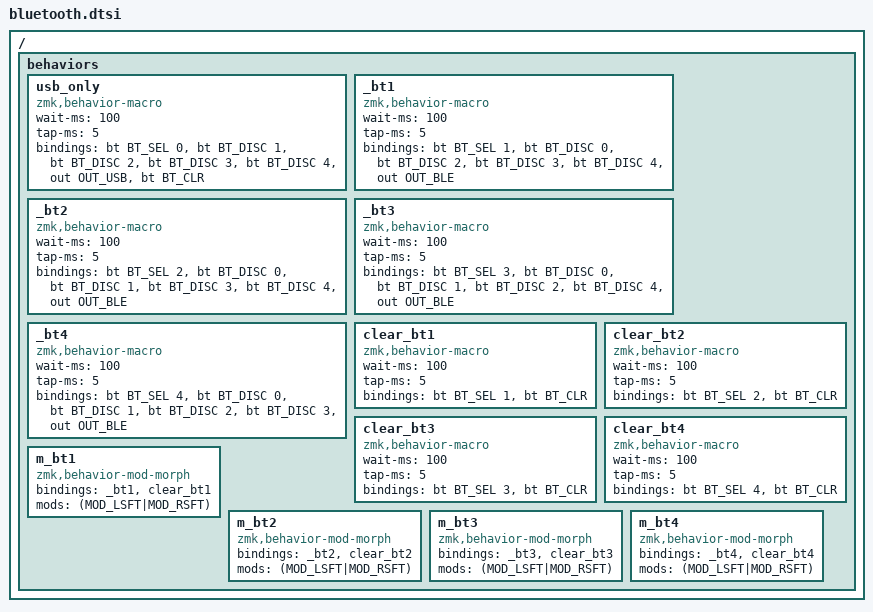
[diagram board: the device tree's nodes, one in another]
#include "include/helper.h"
#include <dt-bindings/zmk/bt.h>

ZMK_MACRO(usb_only,
  wait-ms = <100>;
  tap-ms = <5>;
  bindings = <&bt BT_SEL 0 &bt BT_DISC 1 &bt BT_DISC 2 &bt BT_DISC 3 &bt BT_DISC 4 &out OUT_USB &bt BT_CLR>;
)
ZMK_MACRO(_bt1,
  wait-ms = <100>;
  tap-ms = <5>;
  bindings = <&bt BT_SEL 1 &bt BT_DISC 0 &bt BT_DISC 2 &bt BT_DISC 3 &bt BT_DISC 4 &out OUT_BLE>;
)
ZMK_MACRO(_bt2,
  wait-ms = <100>;
  tap-ms = <5>;
  bindings = <&bt BT_SEL 2 &bt BT_DISC 0 &bt BT_DISC 1 &bt BT_DISC 3 &bt BT_DISC 4 &out OUT_BLE>;
)
ZMK_MACRO(_bt3,
  wait-ms = <100>;
  tap-ms = <5>;
  bindings = <&bt BT_SEL 3 &bt BT_DISC 0 &bt BT_DISC 1 &bt BT_DISC 2 &bt BT_DISC 4 &out OUT_BLE>;
)
ZMK_MACRO(_bt4,
  wait-ms = <100>;
  tap-ms = <5>;
  bindings = <&bt BT_SEL 4 &bt BT_DISC 0 &bt BT_DISC 1 &bt BT_DISC 2 &bt BT_DISC 3 &out OUT_BLE>;
)
ZMK_MACRO(clear_bt1,
  wait-ms = <100>;
  tap-ms = <5>;
  bindings = <&bt BT_SEL 1 &bt BT_CLR>;
)
ZMK_MACRO(clear_bt2,
  wait-ms = <100>;
  tap-ms = <5>;
  bindings = <&bt BT_SEL 2 &bt BT_CLR>;
)
ZMK_MACRO(clear_bt3,
  wait-ms = <100>;
  tap-ms = <5>;
  bindings = <&bt BT_SEL 3 &bt BT_CLR>;
)
ZMK_MACRO(clear_bt4,
  wait-ms = <100>;
  tap-ms = <5>;
  bindings = <&bt BT_SEL 4 &bt BT_CLR>;
)

ZMK_MOD_MORPH(m_bt1,
  bindings = <&_bt1>, <&clear_bt1>;
  mods = <(MOD_LSFT|MOD_RSFT)>;
  )

ZMK_MOD_MORPH(m_bt2,
  bindings = <&_bt2>, <&clear_bt2>;
  mods = <(MOD_LSFT|MOD_RSFT)>;
)

ZMK_MOD_MORPH(m_bt3,
  bindings = <&_bt3>, <&clear_bt3>;
  mods = <(MOD_LSFT|MOD_RSFT)>;
)

ZMK_MOD_MORPH(m_bt4,
  bindings = <&_bt4>, <&clear_bt4>;
  mods = <(MOD_LSFT|MOD_RSFT)>;
)
